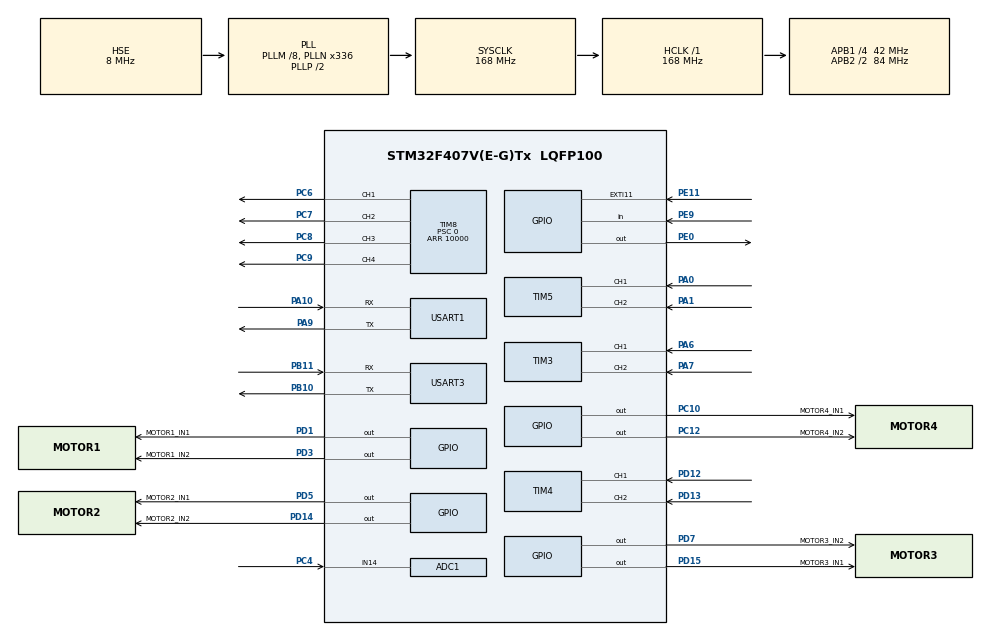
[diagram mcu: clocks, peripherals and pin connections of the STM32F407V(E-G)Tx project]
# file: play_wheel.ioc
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ADC1.Channel-0\#ChannelRegularConversion=ADC_CHANNEL_14
ADC1.NbrOfConversionFlag=1
ADC1.Rank-0\#ChannelRegularConversion=1
ADC1.SamplingTime-0\#ChannelRegularConversion=ADC_SAMPLETIME_3CYCLES
ADC1.master=1
Mcu.Family=STM32F4
Mcu.Name=STM32F407V(E-G)Tx
Mcu.Package=LQFP100
NVIC.EXTI15_10_IRQn=true\:0\:0\:false\:false\:true\:true
NVIC.PriorityGroup=NVIC_PRIORITYGROUP_4
NVIC.TIM8_TRG_COM_TIM14_IRQn=true\:0\:0\:false\:false\:true\:true
PA0-WKUP.Signal=S_TIM5_CH1
PA1.Signal=S_TIM5_CH2
PA10.Mode=Asynchronous
PA10.Signal=USART1_RX
PA13.Mode=Trace_Asynchronous_SW
PA13.Signal=SYS_JTMS-SWDIO
PA14.Mode=Trace_Asynchronous_SW
PA14.Signal=SYS_JTCK-SWCLK
PA6.Signal=S_TIM3_CH1
PA7.Signal=S_TIM3_CH2
PA9.Mode=Asynchronous
PA9.Signal=USART1_TX
PB10.Mode=Asynchronous
PB10.Signal=USART3_TX
PB11.Mode=Asynchronous
PB11.Signal=USART3_RX
PB3.Mode=Trace_Asynchronous_SW
PB3.Signal=SYS_JTDO-SWO
PC10.GPIO_Label=MOTOR4_IN1
PC10.Signal=GPIO_Output
PC12.GPIO_Label=MOTOR4_IN2
PC12.Signal=GPIO_Output
PC4.Signal=ADCx_IN14
PC6.Signal=S_TIM8_CH1
PC7.Signal=S_TIM8_CH2
PC8.Signal=S_TIM8_CH3
PC9.Signal=S_TIM8_CH4
PD1.GPIO_Label=MOTOR1_IN1
PD1.Signal=GPIO_Output
PD12.Signal=S_TIM4_CH1
PD13.Signal=S_TIM4_CH2
PD14.GPIO_Label=MOTOR2_IN2
PD14.Signal=GPIO_Output
PD15.GPIO_Label=MOTOR3_IN1
PD15.Signal=GPIO_Output
PD3.GPIO_Label=MOTOR1_IN2
PD3.Signal=GPIO_Output
PD5.GPIO_Label=MOTOR2_IN1
PD5.Signal=GPIO_Output
PD7.GPIO_Label=MOTOR3_IN2
PD7.Signal=GPIO_Output
PE0.Signal=GPIO_Output
PE11.Signal=GPXTI11
PE9.Signal=GPIO_Input
PH0-OSC_IN.Mode=HSE-External-Oscillator
PH0-OSC_IN.Signal=RCC_OSC_IN
PH1-OSC_OUT.Mode=HSE-External-Oscillator
PH1-OSC_OUT.Signal=RCC_OSC_OUT
ProjectManager.HeapSize=0x200
ProjectManager.StackSize=0x400
ProjectManager.TargetToolchain=MDK-ARM V5
RCC.48MHZClocksFreq_Value=84000000
RCC.AHBFreq_Value=168000000
RCC.APB1CLKDivider=RCC_HCLK_DIV4
RCC.APB1Freq_Value=42000000
RCC.APB1TimFreq_Value=84000000
RCC.APB2CLKDivider=RCC_HCLK_DIV2
RCC.APB2Freq_Value=84000000
RCC.APB2TimFreq_Value=168000000
RCC.CortexFreq_Value=168000000
RCC.HCLKFreq_Value=168000000
RCC.HSE_VALUE=8000000
RCC.HSI_VALUE=16000000
RCC.LSE_VALUE=32768
RCC.PLLM=8
RCC.PLLN=336
RCC.PLLSourceVirtual=RCC_PLLSOURCE_HSE
RCC.SYSCLKFreq_VALUE=168000000
RCC.SYSCLKSource=RCC_SYSCLKSOURCE_PLLCLK
RCC.VCOOutputFreq_Value=336000000
SH.ADCx_IN14.0=ADC1_IN14,IN14
SH.S_TIM3_CH1.0=TIM3_CH1,Encoder_Interface
SH.S_TIM3_CH2.0=TIM3_CH2,Encoder_Interface
SH.S_TIM4_CH1.0=TIM4_CH1,Encoder_Interface
SH.S_TIM4_CH2.0=TIM4_CH2,Encoder_Interface
SH.S_TIM5_CH1.0=TIM5_CH1,Encoder_Interface
SH.S_TIM5_CH2.0=TIM5_CH2,Encoder_Interface
SH.S_TIM8_CH1.0=TIM8_CH1,PWM Generation1 CH1
SH.S_TIM8_CH2.0=TIM8_CH2,PWM Generation2 CH2
SH.S_TIM8_CH3.0=TIM8_CH3,PWM Generation3 CH3
SH.S_TIM8_CH4.0=TIM8_CH4,PWM Generation4 CH4
TIM14.Period=99
TIM14.Prescaler=41999
TIM8.Channel-PWM\ Generation1\ CH1=TIM_CHANNEL_1
TIM8.Channel-PWM\ Generation2\ CH2=TIM_CHANNEL_2
TIM8.Channel-PWM\ Generation3\ CH3=TIM_CHANNEL_3
TIM8.Channel-PWM\ Generation4\ CH4=TIM_CHANNEL_4
TIM8.CounterMode=TIM_COUNTERMODE_CENTERALIGNED1
TIM8.Period=10000
TIM8.Prescaler=0
USART1.VirtualMode=VM_ASYNC
USART3.VirtualMode=VM_ASYNC
VP_TIM14_VS_ClockSourceINT.Mode=Enable_Timer
board=custom

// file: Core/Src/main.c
/**
  ******************************************************************************
  * @file           : main.c
  * @brief          : Main program body
  ******************************************************************************
  ** This notice applies to any and all portions of this file
  * that are not between comment pairs USER CODE BEGIN and
  * USER CODE END. Other portions of this file, whether
  * inserted by the user or by software development tools
  * are owned by their respective copyright owners.
  *
  * COPYRIGHT(c) 2018 STMicroelectronics
  *
  * Redistribution and use in source and binary forms, with or without modification,
  * are permitted provided that the following conditions are met:
  *   1. Redistributions of source code must retain the above copyright notice,
  *      this list of conditions and the following disclaimer.
  *   2. Redistributions in binary form must reproduce the above copyright notice,
  *      this list of conditions and the following disclaimer in the documentation
  *      and/or other materials provided with the distribution.
  *   3. Neither the name of STMicroelectronics nor the names of its contributors
  *      may be used to endorse or promote products derived from this software
  *      without specific prior written permission.
  *
  * THIS SOFTWARE IS PROVIDED BY THE COPYRIGHT HOLDERS AND CONTRIBUTORS "AS IS"
  * AND ANY EXPRESS OR IMPLIED WARRANTIES, INCLUDING, BUT NOT LIMITED TO, THE
  * IMPLIED WARRANTIES OF MERCHANTABILITY AND FITNESS FOR A PARTICULAR PURPOSE ARE
  * DISCLAIMED. IN NO EVENT SHALL THE COPYRIGHT HOLDER OR CONTRIBUTORS BE LIABLE
  * FOR ANY DIRECT, INDIRECT, INCIDENTAL, SPECIAL, EXEMPLARY, OR CONSEQUENTIAL
  * DAMAGES (INCLUDING, BUT NOT LIMITED TO, PROCUREMENT OF SUBSTITUTE GOODS OR
  * SERVICES; LOSS OF USE, DATA, OR PROFITS; OR BUSINESS INTERRUPTION) HOWEVER
  * CAUSED AND ON ANY THEORY OF LIABILITY, WHETHER IN CONTRACT, STRICT LIABILITY,
  * OR TORT (INCLUDING NEGLIGENCE OR OTHERWISE) ARISING IN ANY WAY OUT OF THE USE
  * OF THIS SOFTWARE, EVEN IF ADVISED OF THE POSSIBILITY OF SUCH DAMAGE.
  *
  ******************************************************************************
  */
#include "main.h"
#include "stm32f4xx_hal.h"
#include "adc.h"
#include "tim.h"
#include "usart.h"
#include "gpio.h"

/* USER CODE BEGIN Includes */
#include "defines.h"
#include "robo_init.h"
/* USER CODE END Includes */

/* USER CODE BEGIN PV */
/* Private variables ---------------------------------------------------------*/

/* USER CODE END PV */

void SystemClock_Config(void);

/* USER CODE BEGIN PFP */
/* Private function prototypes -----------------------------------------------*/
void play(void);
/* USER CODE END PFP */

int main(void)
{

        /* MCU Configuration----------------------------------------------------------*/

        /* Reset of all peripherals, Initializes the Flash interface and the Systick. */
        HAL_Init();

        /* Configure the system clock */
        SystemClock_Config();

        /* Initialize all configured peripherals */
        MX_GPIO_Init();
        MX_ADC1_Init();
        MX_TIM3_Init();
        MX_TIM4_Init();
        MX_TIM5_Init();
        MX_TIM8_Init();
        MX_USART1_UART_Init();
        MX_USART3_UART_Init();
        MX_TIM14_Init();
        /* USER CODE BEGIN 2 */
        // sHAL_Delay(1000);
        HAL_TIM_Base_Start(&htim8);
        wheel_init();

        HAL_TIM_PWM_Start(&htim8, TIM_CHANNEL_1);
        HAL_TIM_PWM_Start(&htim8, TIM_CHANNEL_2);
        HAL_TIM_PWM_Start(&htim8, TIM_CHANNEL_3);
        HAL_TIM_PWM_Start(&htim8, TIM_CHANNEL_4);

        HAL_TIM_Base_Start_IT(&htim14);

        play();

        /* USER CODE END 2 */

        /* Infinite loop */
        while (1)
        {

        }
}

void SystemClock_Config(void)
{

        RCC_OscInitTypeDef RCC_OscInitStruct;
        RCC_ClkInitTypeDef RCC_ClkInitStruct;

        /**Configure the main internal regulator output voltage
    */
        __HAL_RCC_PWR_CLK_ENABLE();

        __HAL_PWR_VOLTAGESCALING_CONFIG(PWR_REGULATOR_VOLTAGE_SCALE1);

        /**Initializes the CPU, AHB and APB busses clocks
    */
        RCC_OscInitStruct.OscillatorType = RCC_OSCILLATORTYPE_HSE;
        RCC_OscInitStruct.HSEState = RCC_HSE_ON;
        RCC_OscInitStruct.PLL.PLLState = RCC_PLL_ON;
        RCC_OscInitStruct.PLL.PLLSource = RCC_PLLSOURCE_HSE;
        RCC_OscInitStruct.PLL.PLLM = 8;
        RCC_OscInitStruct.PLL.PLLN = 336;
        RCC_OscInitStruct.PLL.PLLP = RCC_PLLP_DIV2;
        RCC_OscInitStruct.PLL.PLLQ = 4;
        if (HAL_RCC_OscConfig(&RCC_OscInitStruct) != HAL_OK)
        {
                _Error_Handler(__FILE__, __LINE__);
        }

        /**Initializes the CPU, AHB and APB busses clocks
    */
        RCC_ClkInitStruct.ClockType = RCC_CLOCKTYPE_HCLK | RCC_CLOCKTYPE_SYSCLK | RCC_CLOCKTYPE_PCLK1 | RCC_CLOCKTYPE_PCLK2;
        RCC_ClkInitStruct.SYSCLKSource = RCC_SYSCLKSOURCE_PLLCLK;
        RCC_ClkInitStruct.AHBCLKDivider = RCC_SYSCLK_DIV1;
        RCC_ClkInitStruct.APB1CLKDivider = RCC_HCLK_DIV4;
        RCC_ClkInitStruct.APB2CLKDivider = RCC_HCLK_DIV2;

        if (HAL_RCC_ClockConfig(&RCC_ClkInitStruct, FLASH_LATENCY_5) != HAL_OK)
        {
                _Error_Handler(__FILE__, __LINE__);
        }

        /**Configure the Systick interrupt time
    */
        HAL_SYSTICK_Config(HAL_RCC_GetHCLKFreq() / 1000);

        /**Configure the Systick
    */
        HAL_SYSTICK_CLKSourceConfig(SYSTICK_CLKSOURCE_HCLK);

        /* SysTick_IRQn interrupt configuration */
        HAL_NVIC_SetPriority(SysTick_IRQn, 0, 0);
}

void _Error_Handler(char *file, int line)
{
        while (1)
        {
        }
}

/************************ (C) COPYRIGHT STMicroelectronics *****END OF FILE****/
